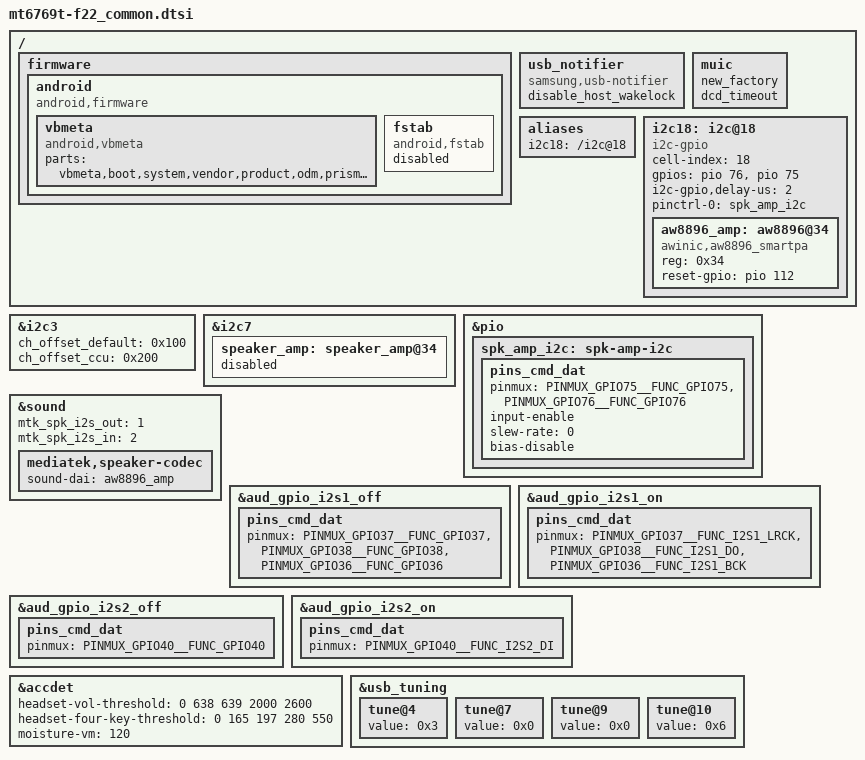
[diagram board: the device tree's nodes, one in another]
/* Generated by Samsung for MTK vendor board
 * If these files should be changed, then please make a sync with MTK
*/


#include "display_lcd_f22_common.dtsi"

/* Add Samsung configuration over here */
/ {
	fragment@model {
		target-path = "/";
		__overlay__ {
			firmware {
				android {
					compatible = "android,firmware";
					vbmeta {
						compatible = "android,vbmeta";
						parts = "vbmeta,boot,system,vendor,product,odm,prism,optics,vbmeta_system,recovery,lk,tee1";
					};
					fstab {
						compatible = "android,fstab";
						status = "disabled";
					};
				};
			};
			usb_notifier {
				compatible = "samsung,usb-notifier";
				disable_host_wakelock;
			};
			muic {
				new_factory;
				dcd_timeout;
			};
			aliases {
				i2c18 = "/i2c@18";
			};

			/* AW8896 SPK AMP */
			i2c18: i2c@18 {
				cell-index = <18>;
				status = "okay";
				compatible = "i2c-gpio";
				gpios = <&pio 76 0 /* sda */
					&pio 75 0>; /* scl */
				i2c-gpio,delay-us = <2>;

				#address-cells = <1>;
				#size-cells = <0>;
				pinctrl-names = "default";
				pinctrl-0 = <&spk_amp_i2c>;

				aw8896_amp: aw8896@34 {
					#sound-dai-cells = <0>;
					compatible = "awinic,aw8896_smartpa";
					reg = <0x34>;
					reset-gpio = <&pio 112 0>;
					status = "okay";
				};
			};
		};
	};
};

&i2c3 {
	ch_offset_default = <0x100>;
	ch_offset_ccu = <0x200>;
};

&i2c7 {
	speaker_amp: speaker_amp@34 {
		status = "disabled";
	};
};

&pio {
	spk_amp_i2c: spk-amp-i2c {
		pins_cmd_dat {
			pinmux = <PINMUX_GPIO75__FUNC_GPIO75>, /* SPK_AMP_I2C_SCL_1P8 */
				<PINMUX_GPIO76__FUNC_GPIO76>; /* SPK_AMP_I2C_SDA_1P8 */
			input-enable;
			slew-rate = <0>;
			bias-disable;
		};
	};
};

&sound {
	mtk_spk_i2s_out = <1>;
	mtk_spk_i2s_in = <2>;
	mediatek,speaker-codec {
		sound-dai = <&aw8896_amp>;
	};
};

/* I2S gpio configuration */
&aud_gpio_i2s1_off {
	pins_cmd_dat {
		pinmux = <PINMUX_GPIO37__FUNC_GPIO37>,
			 <PINMUX_GPIO38__FUNC_GPIO38>,
			 <PINMUX_GPIO36__FUNC_GPIO36>;
	};
};

&aud_gpio_i2s1_on {
	pins_cmd_dat {
		pinmux = <PINMUX_GPIO37__FUNC_I2S1_LRCK>,
			 <PINMUX_GPIO38__FUNC_I2S1_DO>,
			 <PINMUX_GPIO36__FUNC_I2S1_BCK>;
	};
};

&aud_gpio_i2s2_off {
	pins_cmd_dat {
		pinmux = <PINMUX_GPIO40__FUNC_GPIO40>;
	};
};

&aud_gpio_i2s2_on {
	pins_cmd_dat {
		pinmux = <PINMUX_GPIO40__FUNC_I2S2_DI>;
	};
};

&accdet {
	/*min_3pole--max_3pole--min_4pole--max_4pole--vol_bias*/
	headset-vol-threshold = <0 638 639 2000 2600>;
	/*0--MD_MAX--VOICE_MAX--UP_MAX--DW_MAX*/
	headset-four-key-threshold = <0 165 197 280 550>;

	/* moisture SW mode config start, use external resister or not.
	 */
	moisture-vm = <120>;
	/* moisture SW mode config end */
};

&usb_tuning {
	/* term_vref_sel */
	tune@4 {
		value = <0x3>;
	};
	/* hstx_srctrl */
	tune@7 {
		value = <0x0>;
	};
	/* sqth */
	tune@9 {
		value = <0x0>;
	};
	/* discth */
	tune@10 {
		value = <0x6>;
	};
};
